# liliumFP1_application register map
Vendor: Nordic Semiconductor; Series: liliumFP1; File version: 1
CPU: CM33 r0p4, little endian, MPU, FPU, 3 interrupt priority bits, 480 interrupts
Registers are 32-bit, read-write, reset 0x0 unless marked. A register's access mark holds for its fields unless they carry their own. Offsets are from the block's base; [hi:lo] are bit positions; lines under a group give offsets from that group; {n}, {i} and the like mark numbered series; 'fields as' and 'values as' point back to an identical list.

## BICR_NS — Board information configuration registers
Base 0x0FFF87B0; alternate view of UICR_NS
0x00 POWER group — Unspecified
  0x00 CONFIG reset 0xFFFFFFFF — Power configuration of power rails.
    [31] INDUCTOR — DC/DC inductor presence.
      1=NotPresent (DC/DC inductor is not present.); 0=Present (DC/DC inductor is present.)
    [19:16] VDDVS0V8 — VDD_VS_0V8 power configuration.
      15=Unconfigured (Power rail is unconfigured.); 0=Internal (Power rail is configured to use the internal regulator.); 1=External (Power rail is configured to be externally powered.)
    [15:12] VDDAO0V8 — VDD_AO_0V8 power configuration.
      values as VDDVS0V8
    [11:8] VDDRF1V0 — VDD_RF_1V0 power configuration.
      15=Unconfigured (Power rail is unconfigured.); 1=External (Power rail is configured to be externally powered.); 2=Shorted (Power rail is shorted to VDD_1V0.)
    [7:4] VDD1V0 — VDD_1V0 power configuration.
      values as VDDVS0V8
    [3:0] VDDAO1V8 — VDD_AO_1V8 power configuration.
      values as VDDVS0V8
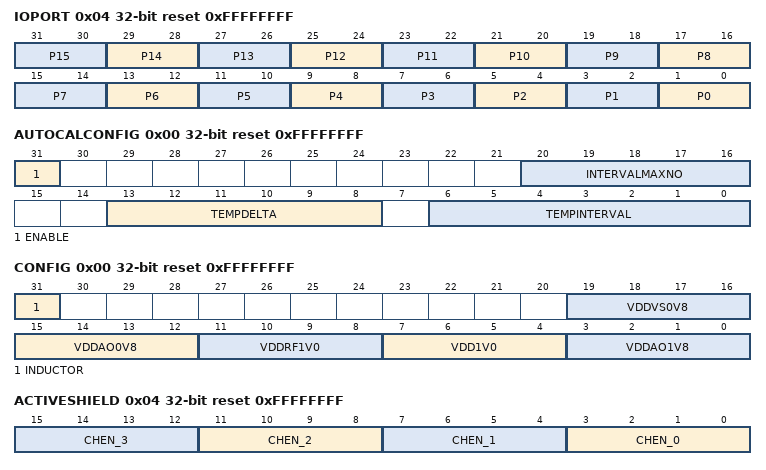
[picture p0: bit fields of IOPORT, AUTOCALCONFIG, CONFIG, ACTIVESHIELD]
  0x04 IOPORT reset 0xFFFFFFFF — Power configuration of IO ports.
    [all] fields
      3=Unconfigured (Port supply is unconfigured.); 0=Disconnected (Port supply rail is not connected. Port cannot be used.); 1=External (Port supply is provided externally.); 2=Shorted (Port supply is shorted to VDD_AO_1V8.)
    [2n+1:2n] P{n} (n=0..15) — P{n} power configuration.
  {0x8+4j} MISPROT[{j}] (j=0..1) reset 0xFFFFFFFF — Description collection: Misconfiguration protection for power configuration. Whenever chaning any register in the POWER group, these registers MUST be written to 0xFFFFFFFF to indicate the system to perform the misconfiguration protection sequence.
    [31:0] MISPROT
      0xFFFFFFFF=Modified (Power configuration has been modified.); 0x471B4B2A=Evaluated (Power configuration has been evaluated.)
0x14 LFXO group — Unspecified
  0x00 CONFIG reset 0xFFFFFFFF — LFXO configuration.
    [19:12] LOADCAP — Built-in load capacitors selection in 1 pF steps. Max. value 25 pF.
      255=Unconfigured (The built-in load capacitors is unconfigured. LFXO will not start unless LOADCAP is configured.); 0=External (Do not use the built-in load capacitors, only external capacitors will be used.)
    [10:8] MODE — LFXO mode.
      7=Unconfigured (The mode is unconfigured.); 0=Pierce (LFXO Pierce mode.); 1=PIXO (LFXO PIXO mode.); 2=ExtSine (LFXO in external sine wave mode.); 3=ExtSquare (LFXO in external square wave mode.)
    [7:4] ACCURACY — LFXO crystal or external signal accuracy.
      15=Unconfigured (The accuracy is unconfigured.); 0=500ppm (LFXO crystal or external signal has an accuracy of 500 ppm.); 1=250ppm (LFXO crystal or external signal has an accuracy of 250 ppm.); 2=150ppm (LFXO crystal or external signal has an accuracy of 150 ppm.); 3=100ppm (LFXO crystal or external signal has an accuracy of 100 ppm.); 4=75ppm (LFXO crystal or external signal has an accuracy of 75 ppm.); 5=50ppm (LFXO crystal or external signal has an accuracy of 50 ppm.); 6=30ppm (LFXO crystal or external signal has an accuracy of 30 ppm.); 7=20ppm (LFXO crystal or external signal has an accuracy of 20 ppm.)
    [0] PRESENCE — LFXO crystal or external signal presence.
      1=NotPresent (LFXO crystal or external signal is not present.); 0=Present (LFXO crystal or external signal is present.)
  0x04 CALIBRATION reset 0xFFFFFFFF — LFXO calibration needed. Must be written to 0xFFFFFFFF after any modification of the LFXO board circuit, load capacitance, or crystal swap.
    [31:0] CALIBRATION
      0xFFFFFFFF=Calibrate the LFXO at startup
  0x08 STARTUPTIME reset 0xFFFFFFFF — LFXO startup time in us.
    [31:0] TIME
      0xFFFFFFFF=Unconfigured (Startup time has not been configured.)
0x20 LFRC group — Unspecified
  0x00 AUTOCALCONFIG reset 0xFFFFFFFF — LFRC autocalibration configuration.
    [31] ENABLE — LFRC.AUTOCALCONFIG register enable.
      0=Enabled (LFRC.AUTOCALCONFIG register has been configured and can be used.); 1=Disabled (LFRC.AUTOCALCONFIG register has not been configured and cannot be used.)
    [20:16] INTERVALMAXNO — Maximum number of TEMPINTERVAL periods in between calibrations, independent of temperature changes.
    [13:8] TEMPDELTA — Temperature delta that should trigger a calibration in 0.25 degrees steps.
    [6:0] TEMPINTERVAL — Temperature measurement interval in 0.25 s steps.
0x24 HFXO group — Unspecified
  0x00 CONFIG reset 0xFFFFFFFF — HFXO configuration.
    [19:12] LOADCAP — Built-in load capacitors selection in 1 pF steps. Max. value 25 pF.
      255=Unconfigured (The built-in load capacitors is unconfigured. HFXO will not start unless LOADCAP is configured.); 0=External (Do not use the built-in load capacitors, only external capacitors will be used.)
    [10:8] MODE — HFXO mode.
      7=Unconfigured (The mode is unconfigured.); 0=Pierce (HFXO Pierce mode.); 1=PIXO (HFXO PIXO mode.); 3=ExtSquare (HFXO in external square wave mode.); 6=Auto (Either Pierce or PIXO automatically handled by the system based on system requests.)
  0x04 STARTUPTIME reset 0xFFFFFFFF — HFXO startup time in us.
    fields as LFXO.STARTUPTIME
0x30 TAMPC group — Unspecified
  0x00 TAMPERSWITCH reset 0xFFFFFFFF — Configuration for external tamper switch detector.
    [3:0] TAMPERSWITCH — Tamper switch enable.
      15=Disabled (Tamper switch is disabled.); 0=Enabled (Tamper switch is enabled. Any value but 0xF is to be considered Enabled.)
  0x04 ACTIVESHIELD reset 0xFFFFFFFF — Configuration for active shield channels.
    [4n+3:4n] CHEN_{n} (n=0..3) — Active shield enable for channel {n}.
      15=Disabled (Active shield channel {n} is disabled.); 0=Enabled (Active shield channel {n} is enabled. Any value but 0xF is to be considered Enabled. If any channel is Enabled, the feature should be Enabled.)

## Notices in the file
Copyright (c) 2010 - 2022, Nordic Semiconductor ASA
All rights reserved.
Redistribution and use in source and binary forms, with or without modification,
are permitted provided that the following conditions are met:
1. Redistributions of source code must retain the above copyright notice, this
list of conditions and the following disclaimer.
2. Redistributions in binary form, except as embedded into a Nordic
Semiconductor ASA integrated circuit in a product or a software update for
such product, must reproduce the above copyright notice, this list of
conditions and the following disclaimer in the documentation and/or other
materials provided with the distribution.
3. Neither the name of Nordic Semiconductor ASA nor the names of its
contributors may be used to endorse or promote products derived from this
software without specific prior written permission.
4. This software, with or without modification, must only be used with a
Nordic Semiconductor ASA integrated circuit.
5. Any software provided in binary form under this license must not be reverse
engineered, decompiled, modified and/or disassembled.
THIS SOFTWARE IS PROVIDED BY NORDIC SEMICONDUCTOR ASA "AS IS" AND ANY EXPRESS
OR IMPLIED WARRANTIES, INCLUDING, BUT NOT LIMITED TO, THE IMPLIED WARRANTIES
OF MERCHANTABILITY, NONINFRINGEMENT, AND FITNESS FOR A PARTICULAR PURPOSE ARE
DISCLAIMED. IN NO EVENT SHALL NORDIC SEMICONDUCTOR ASA OR CONTRIBUTORS BE
LIABLE FOR ANY DIRECT, INDIRECT, INCIDENTAL, SPECIAL, EXEMPLARY, OR
CONSEQUENTIAL DAMAGES (INCLUDING, BUT NOT LIMITED TO, PROCUREMENT OF SUBSTITUTE
GOODS OR SERVICES; LOSS OF USE, DATA, OR PROFITS; OR BUSINESS INTERRUPTION)
HOWEVER CAUSED AND ON ANY THEORY OF LIABILITY, WHETHER IN CONTRACT, STRICT
LIABILITY, OR TORT (INCLUDING NEGLIGENCE OR OTHERWISE) ARISING IN ANY WAY OUT
OF THE USE OF THIS SOFTWARE, EVEN IF ADVISED OF THE POSSIBILITY OF SUCH DAMAGE.
